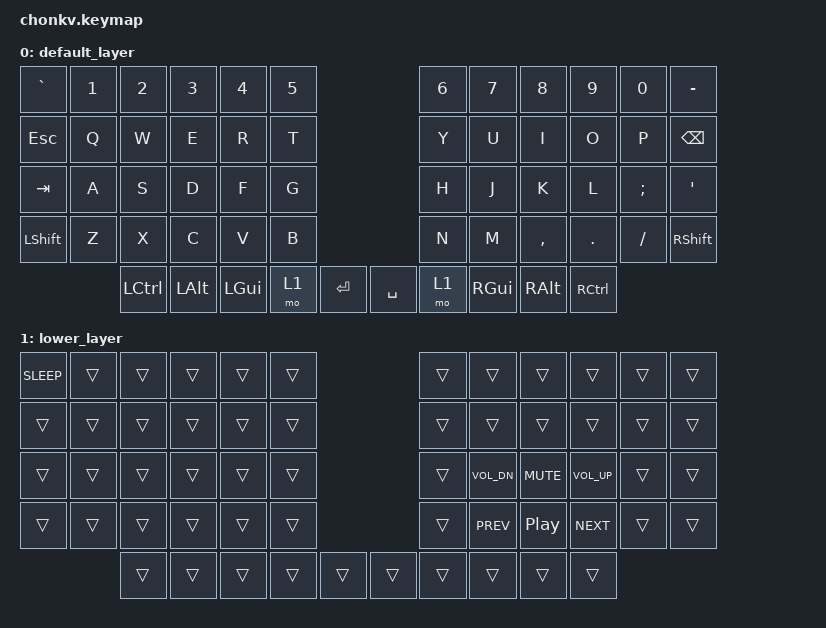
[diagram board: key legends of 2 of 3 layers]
#include <behaviors.dtsi>
#include <dt-bindings/zmk/keys.h>
#include <dt-bindings/zmk/bt.h>

/ {
    keymap {
        compatible = "zmk,keymap";

        default_layer {
          // ,-----------------------------------------.               ,-----------------------------------------.
          // |  `   |  1   |  2   |  3   |  4   |  5   |               |  6   |  7   |  8   |  9   |  0   |  -   |
          // |------+------+------+------+------+------|               |------+------+------+------+------+------|
          // | Esc  |  Q   |  W   |  E   |  R   |  T   |               |  Y   |  U   |  I   |  O   |  P   | BSPC |
          // |------+------+------+------+------+------|               |------+------+------+------+------+------|
          // | Tab  |  A   |  S   |  D   |  F   |  G   |               |  H   |  J   |  K   |  L   |  ;   |  '   |
          // |------+------+------+------+------+------+------. .------+------+------+------+------+------+------|
          // | Shift|  Z   |  X   |  C   |  V   |  B   |      | |      |  N   |  M   |  ,   |  .   |  /   | Shift|
          // `-------------+------+------+------+------| Enter| | Space|------+------+------+------+------+------'
          //               | Ctrl | Alt  | Cmd  | Lower|      | |      | Raise| Cmd  | Alt  | Ctrl |
          //               `----------------------------------' '----------------------------------'
          bindings = <
            &kp GRAVE &kp N1 &kp N2    &kp N3   &kp N4   &kp N5                   &kp N6 &kp N7   &kp N8    &kp N9    &kp N0   &kp MINUS
            &kp ESC   &kp Q  &kp W     &kp E    &kp R    &kp T                    &kp Y  &kp U    &kp I     &kp O     &kp P    &kp BSPC
            &kp TAB   &kp A  &kp S     &kp D    &kp F    &kp G                    &kp H  &kp J    &kp K     &kp L     &kp SEMI &kp SQT
            &kp LSHFT &kp Z  &kp X     &kp C    &kp V    &kp B                    &kp N  &kp M    &kp COMMA &kp DOT   &kp FSLH &kp RSHFT
                            &kp LCTRL  &kp LALT &kp LGUI &mo 1  &kp RET &kp SPACE &mo 1  &kp RGUI &kp RALT  &kp RCTRL
          >;
        };

        lower_layer {
          // ,-----------------------------------------.               ,-----------------------------------------.
          // |      |  F1  |  F2  |  F3  |  F4  |  F5  |               |  F6  |  F7  |  F8  |  F9  | F10  | F11  |
          // |------+------+------+------+------+------|               |------+------+------+------+------+------|
          // |      |  1   |  2   |  3   |  4   |  5   |               |  6   |  7   |  8   |  9   |  0   | F12  |
          // |------+------+------+------+------+------|               |------+------+------+------+------+------|
          // |      |  !   |  @   |  #   |  $   |  %   |               |  ^   |  &   |  *   |  (   |  )   |  |   |
          // |------+------+------+------+------+------+------. .------+------+------+------+------+------+------|
          // |      |  =   |  -   |  +   |  {   |  }   |      | |      |  [   |  ]   |  ;   |  :   |  \   |      |
          // `-------------+------+------+------+------|      | |      |------+------+------+------+------+------'
          //               |      |      |      |      |      | |      | Raise|      |      |      |
          //               `----------------------------------' '----------------------------------'
          bindings = <
            &trans &kp F1    &kp F2    &kp F3      &kp F4   &kp F5                 &kp F6    &kp F7   &kp F8    &kp F9    &kp F10  &kp F11
            &trans &kp N1    &kp N2    &kp N3      &kp N4   &kp N5                 &kp N6    &kp N7   &kp N8    &kp N9    &kp N0   &kp F12
            &trans &kp EXCL  &kp AT    &kp HASH    &kp DLLR &kp PRCNT              &kp CARET &kp AMPS &kp ASTRK &kp LPAR  &kp RPAR &kp PIPE
            &trans &kp EQUAL &kp MINUS &kp KP_PLUS &kp LBRC &kp RBRC               &kp LBKT  &kp RBKT &kp SEMI  &kp COLON &kp BSLH &trans
                             &trans    &trans      &trans   &trans   &trans &trans &mo 3     &trans   &trans    &trans
          >;
        };

        upper_layer {
          // ,-----------------------------------------.               ,-----------------------------------------.
          // |BT CLR| BT1  | BT2  | BT3  | BT4  | BT5  |               |      |      |      |      |      |      |
          // |------+------+------+------+------+------|               |------+------+------+------+------+------|
          // |      | INS  | PSCRN| MENU |      | Scll |               | PG UP|      |  Up  |      |      | Del  |
          // |------+------+------+------+------+------|               |------+------+------+------+------+------|
          // |      |      |      |      |      | Caps |               | PG DN| Left | Down | Right|      |      |
          // |------+------+------+------+------+------+------. .------+------+------+------+------+------+------|
          // |      |      |      |      |      |      |      | |      |      | LStr |      | LEnd |      |      |
          // `-------------+------+------+------+------|      | |      |------+------+------+------+------+------'
          //               |      |      |      | Lower|      | |      |      |      |      |      |
          //               `----------------------------------' '----------------------------------'
          bindings = <
            &bt BT_CLR &bt BT_SEL 0 &bt BT_SEL 1 &bt BT_SEL 2 &bt BT_SEL 3 &bt BT_SEL 4               &trans    &trans   &trans   &trans    &trans &trans
            &trans     &kp INS      &kp PSCRN    &kp K_CMENU  &trans       &kp SLCK                   &kp PG_UP &trans   &kp UP   &trans    &kp DEL
            &trans     &trans       &trans       &trans       &trans       &kp CLCK                   &kp PG_DN &kp LEFT &kp DOWN &kp RIGHT &trans &trans
            &trans     &trans       &trans       &trans       &trans       &trans                     &trans    &kp HOME &trans   &kp END   &trans &trans
                                    &trans       &trans       &trans       &mo 3        &trans &trans &trans    &trans   &trans   &trans
          >;
        };

        lower_layer {
          // ,-----------------------------------------.               ,-----------------------------------------.
          // |      |      |      |      |      |      |               |      |      |      |      |      |      |
          // |------+------+------+------+------+------|               |------+------+------+------+------+------|
          // | RESET|      |      |      |      |      |               |      |      |      |      |      |      |
          // |------+------+------+------+------+------|               |------+------+------+------+------+------|
          // |      |      |      |      |      |      |               |      | VolDn| Mute | VolUp|      |      |
          // |------+------+------+------+------+------+------. .------+------+------+------+------+------+------|
          // | MacSw|      |      |      |      |      |      | |      |      | Prev | Play | Next |      | WinSw|
          // `-------------+------+------+------+------|      | |      |------+------+------+------+------+------'
          //               |      |      |      |      |      | |      |      |      |      |      |
          //               `----------------------------------' '----------------------------------'
          bindings = <
              &kp K_SLEEP &trans &trans &trans &trans &trans               &trans &trans       &trans     &trans       &trans &trans
              &trans      &trans &trans &trans &trans &trans               &trans &trans       &trans     &trans       &trans &trans
              &trans      &trans &trans &trans &trans &trans               &trans &kp C_VOL_DN &kp C_MUTE &kp C_VOL_UP &trans &trans
              &trans      &trans &trans &trans &trans &trans               &trans &kp C_PREV   &kp C_PP   &kp C_NEXT   &trans &trans
                                 &trans &trans &trans &trans &trans &trans &trans &trans       &trans     &trans
            >;
          };
    };
};

&nice_view_spi {
  cs-gpios = <&gpio1 1 GPIO_ACTIVE_HIGH>;
};
